# LFCPNX_100 register map
Vendor: Latticsemi.com; Series: LFCPNX; File version: 1.0
Registers are 32-bit, read-write, reset 0x0 unless marked. A register's access mark holds for its fields unless they carry their own. Offsets are from the block's base; [hi:lo] are bit positions; {n}, {i} and the like mark numbered series.

## SPI_Master_inst
Base 0x00040C00
0x00 WR_DATA_REG wo — Write Data Register
  [31:0] tx_fifo — Write access to this field pushes data to Write FIFO
0x00 RD_DATA_REG ro — Read Data Register
  [31:0] rx_fifo — Read access to this field pops data from Write FIFO
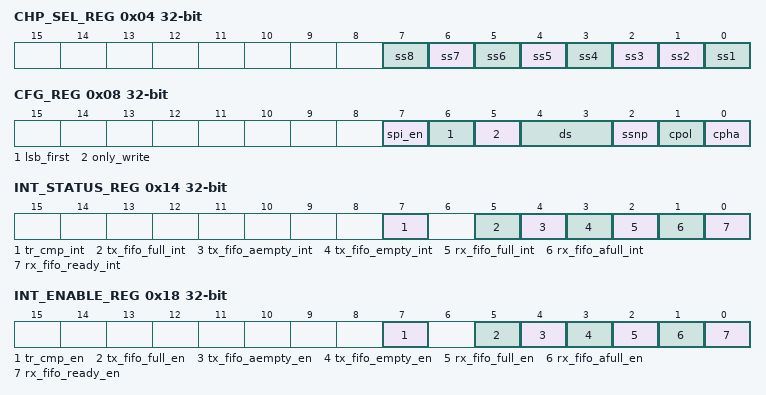
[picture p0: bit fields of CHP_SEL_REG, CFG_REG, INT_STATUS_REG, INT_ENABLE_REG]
0x04 CHP_SEL_REG — Chip Select Register
  [n-1] ss{n} (n=3..8) — Corresponds to the Chip Select: 0-> Target {n} is not selected. 1-> Target {n} is selected.
  [1] ss2 — Corresponds to the Chip Select: 0-> 2 is not selected. 1-> Target 2 is selected.
  [0] ss1 — Corresponds to the Chip Select: 0-> Target 1 is not selected. 1-> Target 1 is selected.
0x08 CFG_REG — Configuration Register
  [7] spi_en — Enables the SPI_ENABLE_REG for Chip Select line control.
  [6] lsb_first — LSB_FIRST, determines whether SPI Controller begins receiving/transmitting data from LSB or MSB.
  [5] only_write — Determines whether SPI Controller receives data from Target or not. 0-> Write/Read. 1->Write Only.
  [4:3] ds — Data Width attribute defines the value of DS fields. 00-> 8-bits. 01-> 16-bits. 10-> 24-bits. 11-> 32-bits.
  [2] ssnp — Controls SSN pulse management. 0->No SSN pulse. 1->SSN pulse generated.
  [1] cpol — Defines Clock Polarity. 0->SCK to zero when idle. 1->SCK to one when idle.
  [0] cpha — Defines Clock phase. 0->The first clock transition is the first data capture edge. 1->The second clock transition is the first data capture edge.
0x0C CLK_PRESCL_REG — Clock Prescaler Lower Register
  [7:0] clk_presc_low — Clock Prescaler Lower Register Bits
0x10 CLK_PRESCH_REG — Clock Prescaler higher Register
  [7:0] clk_presc_high — Clock Prescaler Higher Register Bits
0x14 INT_STATUS_REG — Interrupt Status Register
  [7] tr_cmp_int — This interrupt status bit asserts when the number of transmitted words via SPI interface reaches the TGT_WORD_CNT_REG.target_word_cnt setting value.
  [5] tx_fifo_full_int — This interrupt status bit asserts when Transmit FIFO changes from not full state to full state.
  [4] tx_fifo_aempty_int — This interrupt status bit asserts when the amount of data words in Transmit FIFO changes from 'TX FIFO Almost Empty Flag' - 1 to 'TX FIFO Almost Empty Flag'.
  [3] tx_fifo_empty_int — This interrupt status bit asserts when the last data in Transmit FIFO is popped-out, causing the FIFO to become empty.
  [2] rx_fifo_full_int — This interrupt status bit asserts when RX FIFO full status changes from not full to full state.
  [1] rx_fifo_afull_int — This interrupt status bit asserts when the amount of data words in Receive FIFO changes from 'RX FIFO Almost Full Flag' - 1 to 'RX FIFO Almost Full Flag'.
  [0] rx_fifo_ready_int — This interrupt status bit asserts when Receive FIFO is empty and receives a data word from SPI interface.
0x18 INT_ENABLE_REG — Interrupt Enable Register
  [7] tr_cmp_en — Interrupt enabled bit corresponded to Transfer Complete Interrupt Status.
  [5] tx_fifo_full_en — Interrupt enabled bit corresponded to Transmit FIFO Full Interrupt Status.
  [4] tx_fifo_aempty_en — Interrupt enabled bit corresponded to Transmit FIFO Almost Empty Interrupt Status.
  [3] tx_fifo_empty_en — Interrupt enabled bit corresponded to Transmit FIFO Empty Interrupt Status.
  [2] rx_fifo_full_en — Interrupt enabled bit corresponded to Receive FIFO Full Interrupt Status.
  [1] rx_fifo_afull_en — Interrupt enabled bit corresponded to Receive FIFO Almost Full Interrupt Status.
  [0] rx_fifo_ready_en — Interrupt enabled bit corresponded to Receive FIFO Ready Interrupt Status.
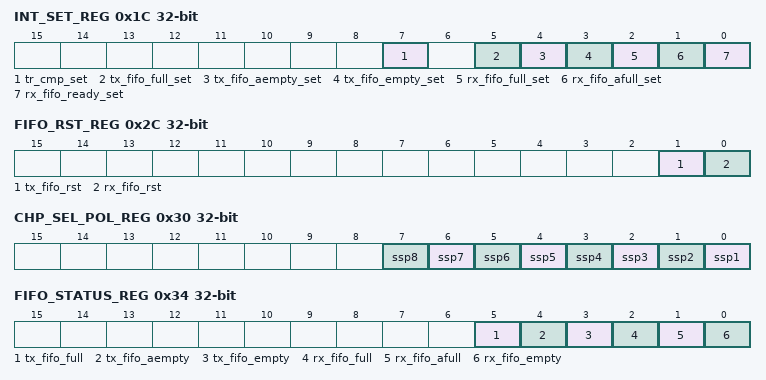
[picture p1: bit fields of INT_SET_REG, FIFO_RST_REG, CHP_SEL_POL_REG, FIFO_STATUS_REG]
0x1C INT_SET_REG wo — Interrupt Set Register
  [7] tr_cmp_set — Interrupt set bit corresponded to Transfer Complete Interrupt Status.
  [5] tx_fifo_full_set — Interrupt set bit corresponded to Transmit FIFO Full Interrupt Status.
  [4] tx_fifo_aempty_set — Interrupt set bit corresponded to Transmit FIFO Almost Empty Interrupt Status.
  [3] tx_fifo_empty_set — Interrupt set bit corresponded to Transmit FIFO Empty Interrupt Status.
  [2] rx_fifo_full_set — Interrupt set bit corresponded to Receive FIFO Full Interrupt Status.
  [1] rx_fifo_afull_set — Interrupt set bit corresponded to Receive FIFO Almost Full Interrupt Status.
  [0] rx_fifo_ready_set — Interrupt set bit corresponded to Receive FIFO Ready Interrupt Status.
0x20 WORD_CNT_REG ro — Word Count Register
  [7:0] word_cnt — The number of words sent from Controller to Target is written in the Word Count Register.
0x24 WORD_CNT_RST_REG wo — Word Count Reset Register
  [7:0] word_cnt_rst — The Word Count Reset Register is used for Word Count Register reset by writing '1' to all bits.
0x28 TGT_WORD_CNT_REG — Target Word Count Register
  [7:0] target_word_cnt — The Target Word Count Register is used for interrupt generation when the target word count is achieved.
0x2C FIFO_RST_REG wo — FIFO Reset Register
  [1] tx_fifo_rst — Write '1' to this bit to crear the Transmit FIFO.
  [0] rx_fifo_rst — Write '1' to this bit to crear the Receive FIFO.
0x30 CHP_SEL_POL_REG — Chip Select Polarity Register
  [n-1] ssp{n} (n=1..8) — Defines the polarity of Chip Select {n}. 0 -> active Low. 1 -> active High.
0x34 FIFO_STATUS_REG ro — FIFO Status Register
  [5] tx_fifo_full — This bit reflects the full condition of Transmit FIFO.
  [4] tx_fifo_aempty — This bit reflects the almost empty condition of Transmit FIFO.
  [3] tx_fifo_empty — This bit reflects the empty condition of Transmit FIFO.
  [2] rx_fifo_full — This bit reflects the full condition of Receive FIFO.
  [1] rx_fifo_afull — This bit reflects the almost full condition of Receive FIFO.
  [0] rx_fifo_empty — This bit reflects the empty condition of Receive FIFO.
0x38 SPI_ENABLE_REG — SPI Enable Register
  [0] spi_en_reg — This bit controls the Chip Select line when CFG_REG.spi_en is set to 1.
